AUTOSAR XML (schema 4-0-3)
standard types defined: Boolean, UInt32, UInt8
package /AUTOSAR_Platform/DataConstrs
  range DC_Boolean: raw 0..1
  range DC_UInt8: raw 0..255
package /PATAC/MSM/ComponentTypes
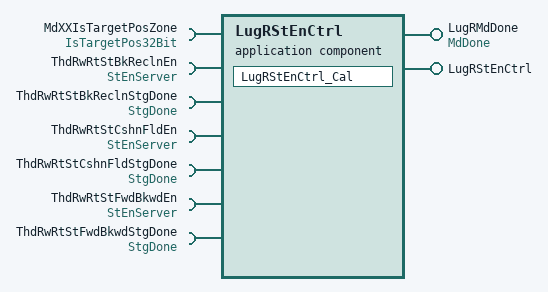
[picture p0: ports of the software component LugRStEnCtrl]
  application sw component type LugRStEnCtrl
    provide port LugRMdDone: nonqueued-sender-com-spec{data-element=MdDone/Val, init-value=0}, provided-interface=MdDone
    provide port LugRStEnCtrl: server-com-spec{operation=Cal, queue-length=1}, provided-interface=LugRStEnCtrl
    7 x require port:
      MdXXIsTargetPosZone: nonqueued-receiver-com-spec{data-element=IsTargetPos32Bit/Val, filter=data-filter-type=ALWAYS, init-value=0}, required-interface=IsTargetPos32Bit
      ThdRwRtStBkReclnEn: required-com-specs=[Clear, Get, Set], required-interface=StEnServer
      ThdRwRtStBkReclnStgDone: nonqueued-receiver-com-spec{data-element=StgDone/Val, filter=data-filter-type=ALWAYS, init-value=0}, required-interface=StgDone
      ThdRwRtStCshnFldEn: required-com-specs=[Clear, Get, Set], required-interface=StEnServer
      ThdRwRtStCshnFldStgDone: nonqueued-receiver-com-spec{data-element=StgDone/Val, filter=data-filter-type=ALWAYS, init-value=0}, required-interface=StgDone
      ThdRwRtStFwdBkwdEn: required-com-specs=[Clear, Get, Set], required-interface=StEnServer
      ThdRwRtStFwdBkwdStgDone: nonqueued-receiver-com-spec{data-element=StgDone/Val, filter=data-filter-type=ALWAYS, init-value=0}, required-interface=StgDone
    behavior LugRStEnCtrl_InternalBehavior
      operation invoked event OIT_LugRStEnCtrl_Cal_LugRStEnCtrl_Cal: start-on-event=LugRStEnCtrl_Cal, operation=LugRStEnCtrl.Cal
      runnable LugRStEnCtrl_Cal
        data-receive-point-by-arguments:
          4 x access:
            REC_MdXXIsTargetPosZone_Val: accessed-variable=MdXXIsTargetPosZone.Val
            REC_ThdRwRtStBkReclnStgDone_Val: accessed-variable=ThdRwRtStBkReclnStgDone.Val
            REC_ThdRwRtStCshnFldStgDone_Val: accessed-variable=ThdRwRtStCshnFldStgDone.Val
            REC_ThdRwRtStFwdBkwdStgDone_Val: accessed-variable=ThdRwRtStFwdBkwdStgDone.Val
        data-send-points:
          access SEND_LugRMdDone_Val: accessed-variable=LugRMdDone.Val
        6 x sync call, all with timeout=0:
          SC_ThdRwRtStBkReclnEn_Clear: operation=ThdRwRtStBkReclnEn.Clear
          SC_ThdRwRtStBkReclnEn_Set: operation=ThdRwRtStBkReclnEn.Set
          SC_ThdRwRtStCshnFldEn_Clear: operation=ThdRwRtStCshnFldEn.Clear
          SC_ThdRwRtStCshnFldEn_Set: operation=ThdRwRtStCshnFldEn.Set
          SC_ThdRwRtStFwdBkwdEn_Clear: operation=ThdRwRtStFwdBkwdEn.Clear
          SC_ThdRwRtStFwdBkwdEn_Set: operation=ThdRwRtStFwdBkwdEn.Set
  swc implementation LugRStEnCtrl_Implementation: behavior=LugRStEnCtrl_InternalBehavior
    code-descriptors:
      code Default: artifact-descriptors=autosar-engineering-object={short-label=Default, category=SWSRC}
package /PATAC/MSM/ModeAdjust/PortInterface
  client server interface LugRStEnCtrl
    operation Cal
  client server interface StEnServer
    operation Clear
      arg data: type=UInt8, direction=IN, server-argument-impl-policy=USE-ARGUMENT-TYPE
    operation Get
      arg data: type=UInt32, direction=OUT, server-argument-impl-policy=USE-ARGUMENT-TYPE
    operation Set
      arg data: type=UInt8, direction=IN, server-argument-impl-policy=USE-ARGUMENT-TYPE
  sender receiver interface IsTargetPos32Bit: invalidation-policy{data-element=IsTargetPos32Bit/Val, handle-invalid=DONT-INVALIDATE}
    data Val: type=UInt32
  sender receiver interface MdDone: invalidation-policy{data-element=MdDone/Val, handle-invalid=DONT-INVALIDATE}
    data Val: type=UInt8
  sender receiver interface StgDone: invalidation-policy{data-element=StgDone/Val, handle-invalid=DONT-INVALIDATE}
    data Val: type=Boolean
